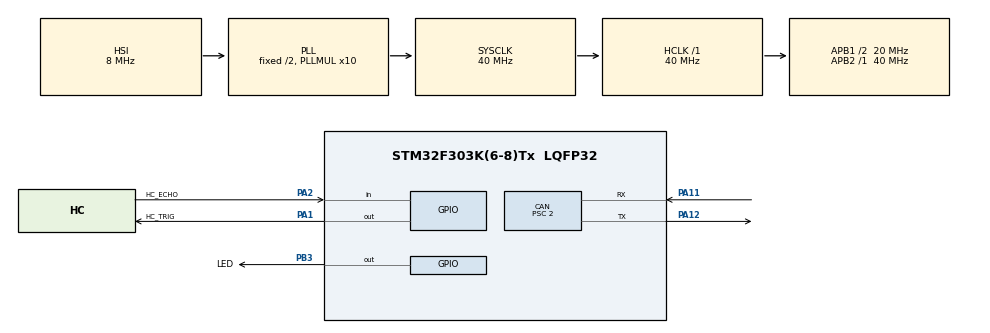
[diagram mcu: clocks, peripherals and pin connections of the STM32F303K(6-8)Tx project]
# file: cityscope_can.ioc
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CAN.BS1=CAN_BS1_8TQ
CAN.CalculateBaudRate=1000000
CAN.CalculateTimeBit=1000
CAN.CalculateTimeQuantum=100.0
CAN.Prescaler=2
FREERTOS.Tasks01=defaultTask,24,128,StartDefaultTask,Default,NULL,Dynamic,NULL,NULL
Mcu.Family=STM32F3
Mcu.Name=STM32F303K(6-8)Tx
Mcu.Package=LQFP32
NVIC.PriorityGroup=NVIC_PRIORITYGROUP_4
PA0.Signal=S_TIM2_CH1_ETR
PA1.GPIO_Label=HC_TRIG
PA1.Signal=GPIO_Output
PA11.Mode=CAN_Activate
PA11.Signal=CAN_RX
PA12.Mode=CAN_Activate
PA12.Signal=CAN_TX
PA2.GPIO_Label=HC_ECHO
PA2.Signal=GPIO_Input
PB3.GPIO_Label=LED
PB3.Signal=GPIO_Output
ProjectManager.HeapSize=0x200
ProjectManager.StackSize=0x400
ProjectManager.TargetToolchain=Makefile
RCC.AHBFreq_Value=40000000
RCC.APB1CLKDivider=RCC_HCLK_DIV2
RCC.APB1Freq_Value=20000000
RCC.APB1TimFreq_Value=40000000
RCC.APB2Freq_Value=40000000
RCC.APB2TimFreq_Value=40000000
RCC.CortexFreq_Value=40000000
RCC.HCLKFreq_Value=40000000
RCC.HSE_VALUE=8000000
RCC.HSI_VALUE=8000000
RCC.PLLMUL=RCC_PLL_MUL10
RCC.SYSCLKFreq_VALUE=40000000
RCC.SYSCLKSourceVirtual=RCC_SYSCLKSOURCE_PLLCLK
SH.S_TIM2_CH1_ETR.0=TIM2_CH1
VP_FREERTOS_VS_CMSIS_V2.Mode=CMSIS_V2
board=custom

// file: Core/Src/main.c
/* USER CODE BEGIN Header */
/**
  ******************************************************************************
  * @file           : main.c
  * @brief          : Main program body
  ******************************************************************************
  * @attention
  *
  * Copyright (c) 2023 STMicroelectronics.
  * All rights reserved.
  *
  * This software is licensed under terms that can be found in the LICENSE file
  * in the root directory of this software component.
  * If no LICENSE file comes with this software, it is provided AS-IS.
  *
  ******************************************************************************
  */
/* USER CODE END Header */
#include "main.h"
#include "cmsis_os.h"
#include "can.h"
#include "gpio.h"

TIM_HandleTypeDef htim1;

/* USER CODE BEGIN PV */
// #define TRIG_PIN GPIO_PIN_9
// #define TRIG_PORT GPIOA
// #define ECHO_PIN GPIO_PIN_8
// #define ECHO_PORT GPIOA
uint32_t pMillis;
uint32_t Value1 = 0;
uint32_t Value2 = 0;
uint16_t Distance  = 0;  // cm
/* USER CODE END PV */

void SystemClock_Config(void);
void MX_FREERTOS_Init(void);

int main(void)
{

  /* MCU Configuration--------------------------------------------------------*/

  /* Reset of all peripherals, Initializes the Flash interface and the Systick. */
  HAL_Init();

  /* Configure the system clock */
  SystemClock_Config();

  /* Initialize all configured peripherals */
  MX_GPIO_Init();
  MX_CAN_Init();

  /* USER CODE BEGIN 2 */
  HAL_TIM_Base_Start(&htim1);
  HAL_GPIO_WritePin(HC_TRIG_GPIO_Port, HC_TRIG_Pin, GPIO_PIN_RESET);  // pull the TRIG pin low
  /* USER CODE END 2 */

  /* Init scheduler */
  osKernelInitialize();  /* Call init function for freertos objects (in freertos.c) */
  MX_FREERTOS_Init();

  /* Start scheduler */
  osKernelStart();

  /* We should never get here as control is now taken by the scheduler */
  /* Infinite loop */
  while (1)
  {
    HAL_GPIO_WritePin(HC_TRIG_GPIO_Port, HC_TRIG_Pin, GPIO_PIN_SET);  // pull the TRIG pin HIGH
    __HAL_TIM_SET_COUNTER(&htim1, 0);
    while (__HAL_TIM_GET_COUNTER (&htim1) < 10);  // wait for 10 us
    HAL_GPIO_WritePin(HC_TRIG_GPIO_Port, HC_TRIG_Pin, GPIO_PIN_RESET);  // pull the TRIG pin low

    pMillis = HAL_GetTick(); // used this to avoid infinite while loop  (for timeout)
    // wait for the echo pin to go high
    while (!(HAL_GPIO_ReadPin (HC_ECHO_GPIO_Port, HC_ECHO_Pin)) && pMillis + 10 >  HAL_GetTick());
    Value1 = __HAL_TIM_GET_COUNTER (&htim1);

    pMillis = HAL_GetTick(); // used this to avoid infinite while loop (for timeout)
    // wait for the echo pin to go low
    while ((HAL_GPIO_ReadPin (HC_ECHO_GPIO_Port, HC_ECHO_Pin)) && pMillis + 50 > HAL_GetTick());
    Value2 = __HAL_TIM_GET_COUNTER (&htim1);

    Distance = (Value2-Value1)* 0.034/2;
    HAL_Delay(50);

    break;
    /* USER CODE END WHILE */
  }
}

void SystemClock_Config(void)
{
  RCC_OscInitTypeDef RCC_OscInitStruct = {0};
  RCC_ClkInitTypeDef RCC_ClkInitStruct = {0};

  /** Initializes the RCC Oscillators according to the specified parameters
  * in the RCC_OscInitTypeDef structure.
  */
  RCC_OscInitStruct.OscillatorType = RCC_OSCILLATORTYPE_HSI;
  RCC_OscInitStruct.HSIState = RCC_HSI_ON;
  RCC_OscInitStruct.HSICalibrationValue = RCC_HSICALIBRATION_DEFAULT;
  RCC_OscInitStruct.PLL.PLLState = RCC_PLL_ON;
  RCC_OscInitStruct.PLL.PLLSource = RCC_PLLSOURCE_HSI;
  RCC_OscInitStruct.PLL.PLLMUL = RCC_PLL_MUL10;
  if (HAL_RCC_OscConfig(&RCC_OscInitStruct) != HAL_OK)
  {
    Error_Handler();
  }

  /** Initializes the CPU, AHB and APB buses clocks
  */
  RCC_ClkInitStruct.ClockType = RCC_CLOCKTYPE_HCLK|RCC_CLOCKTYPE_SYSCLK
                              |RCC_CLOCKTYPE_PCLK1|RCC_CLOCKTYPE_PCLK2;
  RCC_ClkInitStruct.SYSCLKSource = RCC_SYSCLKSOURCE_PLLCLK;
  RCC_ClkInitStruct.AHBCLKDivider = RCC_SYSCLK_DIV1;
  RCC_ClkInitStruct.APB1CLKDivider = RCC_HCLK_DIV2;
  RCC_ClkInitStruct.APB2CLKDivider = RCC_HCLK_DIV1;

  if (HAL_RCC_ClockConfig(&RCC_ClkInitStruct, FLASH_LATENCY_1) != HAL_OK)
  {
    Error_Handler();
  }
}

void Error_Handler(void)
{
  __disable_irq();
  while (1)
  {
  }
}

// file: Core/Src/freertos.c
/* USER CODE BEGIN Header */
/**
  ******************************************************************************
  * File Name          : freertos.c
  * Description        : Code for freertos applications
  ******************************************************************************
  * @attention
  *
  * Copyright (c) 2023 STMicroelectronics.
  * All rights reserved.
  *
  * This software is licensed under terms that can be found in the LICENSE file
  * in the root directory of this software component.
  * If no LICENSE file comes with this software, it is provided AS-IS.
  *
  ******************************************************************************
  */
/* USER CODE END Header */

#include "FreeRTOS.h"
#include "task.h"
#include "main.h"
#include "cmsis_os.h"

/* Definitions for defaultTask */
osThreadId_t defaultTaskHandle;

osThreadId_t customTaskHandle;

const osThreadAttr_t defaultTask_attributes = {
  .name = "defaultTask",
  .stack_size = 128 * 4,
  .priority = (osPriority_t) osPriorityNormal,
};

void StartDefaultTask(void *argument)
{
  for(;;)
  {
    HAL_GPIO_TogglePin(HC_ECHO_GPIO_Port, HC_ECHO_Pin);
    HAL_GPIO_TogglePin(HC_TRIG_GPIO_Port, HC_TRIG_Pin);
    HAL_Delay(200);
  }
};

void StartCustomTask(void *argument)
{
  for(;;)
  {
    HAL_GPIO_TogglePin(LED_GPIO_Port, LED_Pin);
    HAL_Delay(200);
  }
}

void MX_FREERTOS_Init(void); /* (MISRA C 2004 rule 8.1) */

void MX_FREERTOS_Init(void) {

  /* Create the thread(s) */
  /* creation of defaultTask */
  defaultTaskHandle = osThreadNew(StartDefaultTask, NULL, &defaultTask_attributes);

  customTaskHandle = osThreadNew(StartCustomTask, NULL, &defaultTask_attributes);

}

// void StartDefaultTask(void *argument)
// {
//   /* USER CODE BEGIN StartDefaultTask */
//   /* Infinite loop */
//   for(;;)
//   {
//     HAL_GPIO_TogglePin(HC_ECHO_GPIO_Port, HC_TRIG_Pin);
//     osDelay(1000);
//   }
//   /* USER CODE END StartDefaultTask */
// }
